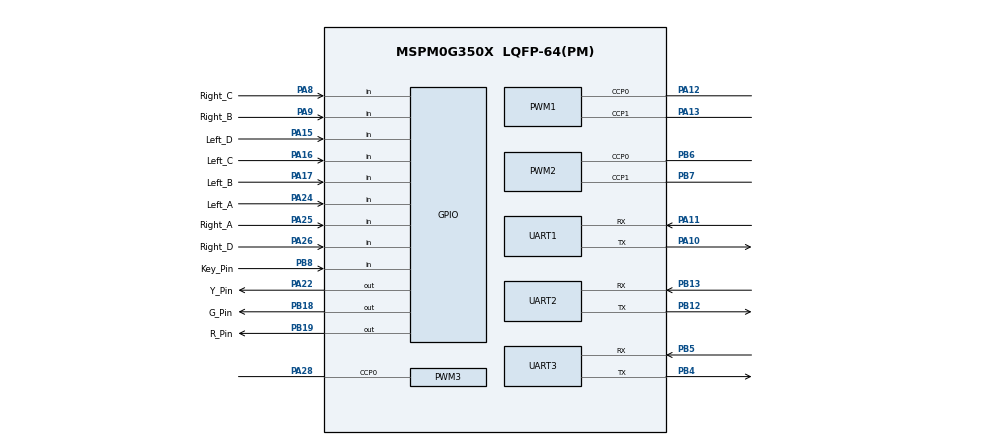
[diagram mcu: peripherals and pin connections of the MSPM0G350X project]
/**
 * @cliArgs --device "MSPM0G350X" --part "Default" --package "LQFP-64(PM)" --product "mspm0_sdk@2.04.00.06"
 * @versions {"tool":"1.21.1+3772"}
 */

/**
 * Import the modules used in this configuration.
 */
const GPIO   = scripting.addModule("/ti/driverlib/GPIO", {}, false);
const GPIO1  = GPIO.addInstance();
const GPIO2  = GPIO.addInstance();
const GPIO3  = GPIO.addInstance();
const GPIO4  = GPIO.addInstance();
const PWM    = scripting.addModule("/ti/driverlib/PWM", {}, false);
const PWM1   = PWM.addInstance();
const PWM2   = PWM.addInstance();
const PWM3   = PWM.addInstance();
const SYSCTL = scripting.addModule("/ti/driverlib/SYSCTL");
const TIMER  = scripting.addModule("/ti/driverlib/TIMER", {}, false);
const TIMER1 = TIMER.addInstance();
const UART   = scripting.addModule("/ti/driverlib/UART", {}, false);
const UART1  = UART.addInstance();
const UART2  = UART.addInstance();
const UART3  = UART.addInstance();

/**
 * Write custom configuration values to the imported modules.
 */
const divider6       = system.clockTree["PLL_CLK2X_DIV"];
divider6.divideValue = 4;

const divider7       = system.clockTree["PLL_PDIV"];
divider7.divideValue = 2;

const divider9       = system.clockTree["UDIV"];
divider9.divideValue = 2;

const multiplier2         = system.clockTree["PLL_QDIV"];
multiplier2.multiplyValue = 10;

const mux8       = system.clockTree["HSCLKMUX"];
mux8.inputSelect = "HSCLKMUX_SYSPLL2X";

GPIO1.$name                              = "Encoder_Left";
GPIO1.port                               = "PORTA";
GPIO1.associatedPins.create(4);
GPIO1.associatedPins[0].direction        = "INPUT";
GPIO1.associatedPins[0].internalResistor = "PULL_UP";
GPIO1.associatedPins[0].interruptEn      = true;
GPIO1.associatedPins[0].polarity         = "FALL";
GPIO1.associatedPins[0].$name            = "Left_A";
GPIO1.associatedPins[0].pin.$assign      = "PA24";
GPIO1.associatedPins[1].direction        = "INPUT";
GPIO1.associatedPins[1].internalResistor = "PULL_UP";
GPIO1.associatedPins[1].interruptEn      = true;
GPIO1.associatedPins[1].$name            = "Left_B";
GPIO1.associatedPins[1].polarity         = "RISE";
GPIO1.associatedPins[1].pin.$assign      = "PA17";
GPIO1.associatedPins[2].direction        = "INPUT";
GPIO1.associatedPins[2].internalResistor = "PULL_UP";
GPIO1.associatedPins[2].interruptEn      = true;
GPIO1.associatedPins[2].$name            = "Left_C";
GPIO1.associatedPins[2].polarity         = "FALL";
GPIO1.associatedPins[2].pin.$assign      = "PA16";
GPIO1.associatedPins[3].direction        = "INPUT";
GPIO1.associatedPins[3].internalResistor = "PULL_UP";
GPIO1.associatedPins[3].interruptEn      = true;
GPIO1.associatedPins[3].polarity         = "RISE";
GPIO1.associatedPins[3].$name            = "Left_D";
GPIO1.associatedPins[3].pin.$assign      = "PA15";

const Board = scripting.addModule("/ti/driverlib/Board", {}, false);

GPIO2.$name                              = "Encoder_Right";
GPIO2.port                               = "PORTA";
GPIO2.associatedPins.create(4);
GPIO2.associatedPins[0].$name            = "Right_A";
GPIO2.associatedPins[0].direction        = "INPUT";
GPIO2.associatedPins[0].internalResistor = "PULL_UP";
GPIO2.associatedPins[0].interruptEn      = true;
GPIO2.associatedPins[0].polarity         = "FALL";
GPIO2.associatedPins[0].pin.$assign      = "PA25";
GPIO2.associatedPins[1].$name            = "Right_B";
GPIO2.associatedPins[1].direction        = "INPUT";
GPIO2.associatedPins[1].internalResistor = "PULL_UP";
GPIO2.associatedPins[1].interruptEn      = true;
GPIO2.associatedPins[1].polarity         = "RISE";
GPIO2.associatedPins[1].pin.$assign      = "PA9";
GPIO2.associatedPins[2].$name            = "Right_C";
GPIO2.associatedPins[2].direction        = "INPUT";
GPIO2.associatedPins[2].internalResistor = "PULL_UP";
GPIO2.associatedPins[2].interruptEn      = true;
GPIO2.associatedPins[2].polarity         = "FALL";
GPIO2.associatedPins[2].pin.$assign      = "PA8";
GPIO2.associatedPins[3].$name            = "Right_D";
GPIO2.associatedPins[3].direction        = "INPUT";
GPIO2.associatedPins[3].internalResistor = "PULL_UP";
GPIO2.associatedPins[3].interruptEn      = true;
GPIO2.associatedPins[3].polarity         = "RISE";
GPIO2.associatedPins[3].pin.$assign      = "PA26";

GPIO3.$name                         = "RGY_LED";
GPIO3.associatedPins.create(3);
GPIO3.associatedPins[0].$name       = "R_Pin";
GPIO3.associatedPins[0].pin.$assign = "PB19";
GPIO3.associatedPins[1].$name       = "G_Pin";
GPIO3.associatedPins[1].pin.$assign = "PB18";
GPIO3.associatedPins[2].$name       = "Y_Pin";
GPIO3.associatedPins[2].pin.$assign = "PA22";

GPIO4.$name                              = "Key";
GPIO4.associatedPins[0].$name            = "Key_Pin";
GPIO4.associatedPins[0].direction        = "INPUT";
GPIO4.associatedPins[0].internalResistor = "PULL_UP";
GPIO4.associatedPins[0].pin.$assign      = "PB8";

PWM1.$name                              = "Driver_Left";
PWM1.timerCount                         = 7200;
PWM1.pwmMode                            = "EDGE_ALIGN_UP";
PWM1.peripheral.$assign                 = "TIMG0";
PWM1.peripheral.ccp0Pin.$assign         = "PA12";
PWM1.peripheral.ccp1Pin.$assign         = "PA13";
PWM1.PWM_CHANNEL_0.$name                = "ti_driverlib_pwm_PWMTimerCC0";
PWM1.PWM_CHANNEL_1.$name                = "ti_driverlib_pwm_PWMTimerCC1";
PWM1.ccp0PinConfig.$name                = "ti_driverlib_gpio_GPIOPinGeneric0";
PWM1.ccp0PinConfig.direction            = scripting.forceWrite("OUTPUT");
PWM1.ccp0PinConfig.hideOutputInversion  = scripting.forceWrite(false);
PWM1.ccp0PinConfig.onlyInternalResistor = scripting.forceWrite(false);
PWM1.ccp0PinConfig.passedPeripheralType = scripting.forceWrite("Digital");
PWM1.ccp1PinConfig.$name                = "ti_driverlib_gpio_GPIOPinGeneric1";
PWM1.ccp1PinConfig.direction            = scripting.forceWrite("OUTPUT");
PWM1.ccp1PinConfig.hideOutputInversion  = scripting.forceWrite(false);
PWM1.ccp1PinConfig.onlyInternalResistor = scripting.forceWrite(false);
PWM1.ccp1PinConfig.passedPeripheralType = scripting.forceWrite("Digital");

PWM2.$name                              = "Driver_Right";
PWM2.clockDivider                       = 2;
PWM2.timerCount                         = 7200;
PWM2.pwmMode                            = "EDGE_ALIGN_UP";
PWM2.peripheral.$assign                 = "TIMG6";
PWM2.peripheral.ccp0Pin.$assign         = "PB6";
PWM2.peripheral.ccp1Pin.$assign         = "PB7";
PWM2.PWM_CHANNEL_0.$name                = "ti_driverlib_pwm_PWMTimerCC2";
PWM2.PWM_CHANNEL_1.$name                = "ti_driverlib_pwm_PWMTimerCC3";
PWM2.ccp0PinConfig.$name                = "ti_driverlib_gpio_GPIOPinGeneric2";
PWM2.ccp0PinConfig.direction            = scripting.forceWrite("OUTPUT");
PWM2.ccp0PinConfig.hideOutputInversion  = scripting.forceWrite(false);
PWM2.ccp0PinConfig.onlyInternalResistor = scripting.forceWrite(false);
PWM2.ccp0PinConfig.passedPeripheralType = scripting.forceWrite("Digital");
PWM2.ccp1PinConfig.$name                = "ti_driverlib_gpio_GPIOPinGeneric3";
PWM2.ccp1PinConfig.direction            = scripting.forceWrite("OUTPUT");
PWM2.ccp1PinConfig.hideOutputInversion  = scripting.forceWrite(false);
PWM2.ccp1PinConfig.onlyInternalResistor = scripting.forceWrite(false);
PWM2.ccp1PinConfig.passedPeripheralType = scripting.forceWrite("Digital");

PWM3.$name                              = "Servo";
PWM3.pwmMode                            = "EDGE_ALIGN_UP";
PWM3.ccIndex                            = [0];
PWM3.timerCount                         = 5000;
PWM3.clockPrescale                      = 80;
PWM3.peripheral.$assign                 = "TIMG7";
PWM3.peripheral.ccp0Pin.$assign         = "PA28";
PWM3.PWM_CHANNEL_0.$name                = "ti_driverlib_pwm_PWMTimerCC4";
PWM3.ccp0PinConfig.$name                = "ti_driverlib_gpio_GPIOPinGeneric4";
PWM3.ccp0PinConfig.direction            = scripting.forceWrite("OUTPUT");
PWM3.ccp0PinConfig.hideOutputInversion  = scripting.forceWrite(false);
PWM3.ccp0PinConfig.onlyInternalResistor = scripting.forceWrite(false);
PWM3.ccp0PinConfig.passedPeripheralType = scripting.forceWrite("Digital");

SYSCTL.forceDefaultClkConfig = true;
SYSCTL.clockTreeEn           = true;

TIMER1.$name              = "Mask_Timer";
TIMER1.timerMode          = "PERIODIC_UP";
TIMER1.timerPeriod        = "10 ms";
TIMER1.timerClkPrescale   = 40;
TIMER1.interrupts         = ["LOAD"];
TIMER1.interruptPriority  = "2";
TIMER1.peripheral.$assign = "TIMG8";

UART1.$name                            = "Debugger_UART";
UART1.enabledInterrupts                = ["RX"];
UART1.targetBaudRate                   = 115200;
UART1.peripheral.$assign               = "UART0";
UART1.peripheral.rxPin.$assign         = "PA11";
UART1.peripheral.txPin.$assign         = "PA10";
UART1.txPinConfig.direction            = scripting.forceWrite("OUTPUT");
UART1.txPinConfig.hideOutputInversion  = scripting.forceWrite(false);
UART1.txPinConfig.onlyInternalResistor = scripting.forceWrite(false);
UART1.txPinConfig.passedPeripheralType = scripting.forceWrite("Digital");
UART1.txPinConfig.$name                = "ti_driverlib_gpio_GPIOPinGeneric5";
UART1.rxPinConfig.hideOutputInversion  = scripting.forceWrite(false);
UART1.rxPinConfig.onlyInternalResistor = scripting.forceWrite(false);
UART1.rxPinConfig.passedPeripheralType = scripting.forceWrite("Digital");
UART1.rxPinConfig.$name                = "ti_driverlib_gpio_GPIOPinGeneric6";

UART2.$name                            = "HWT_UART";
UART2.enabledInterrupts                = ["RX"];
UART2.interruptPriority                = "1";
UART2.peripheral.$assign               = "UART3";
UART2.peripheral.rxPin.$assign         = "PB13";
UART2.peripheral.txPin.$assign         = "PB12";
UART2.txPinConfig.direction            = scripting.forceWrite("OUTPUT");
UART2.txPinConfig.hideOutputInversion  = scripting.forceWrite(false);
UART2.txPinConfig.onlyInternalResistor = scripting.forceWrite(false);
UART2.txPinConfig.passedPeripheralType = scripting.forceWrite("Digital");
UART2.txPinConfig.$name                = "ti_driverlib_gpio_GPIOPinGeneric7";
UART2.rxPinConfig.hideOutputInversion  = scripting.forceWrite(false);
UART2.rxPinConfig.onlyInternalResistor = scripting.forceWrite(false);
UART2.rxPinConfig.passedPeripheralType = scripting.forceWrite("Digital");
UART2.rxPinConfig.$name                = "ti_driverlib_gpio_GPIOPinGeneric8";

UART3.$name                            = "Raspberry_Pi_UART";
UART3.targetBaudRate                   = 115200;
UART3.enabledInterrupts                = ["RX"];
UART3.peripheral.$assign               = "UART1";
UART3.peripheral.rxPin.$assign         = "PB5";
UART3.peripheral.txPin.$assign         = "PB4";
UART3.txPinConfig.direction            = scripting.forceWrite("OUTPUT");
UART3.txPinConfig.hideOutputInversion  = scripting.forceWrite(false);
UART3.txPinConfig.onlyInternalResistor = scripting.forceWrite(false);
UART3.txPinConfig.passedPeripheralType = scripting.forceWrite("Digital");
UART3.txPinConfig.$name                = "ti_driverlib_gpio_GPIOPinGeneric9";
UART3.rxPinConfig.hideOutputInversion  = scripting.forceWrite(false);
UART3.rxPinConfig.onlyInternalResistor = scripting.forceWrite(false);
UART3.rxPinConfig.passedPeripheralType = scripting.forceWrite("Digital");
UART3.rxPinConfig.$name                = "ti_driverlib_gpio_GPIOPinGeneric10";

/**
 * Pinmux solution for unlocked pins/peripherals. This ensures that minor changes to the automatic solver in a future
 * version of the tool will not impact the pinmux you originally saw.  These lines can be completely deleted in order to
 * re-solve from scratch.
 */
Board.peripheral.$suggestSolution          = "DEBUGSS";
Board.peripheral.swclkPin.$suggestSolution = "PA20";
Board.peripheral.swdioPin.$suggestSolution = "PA19";
